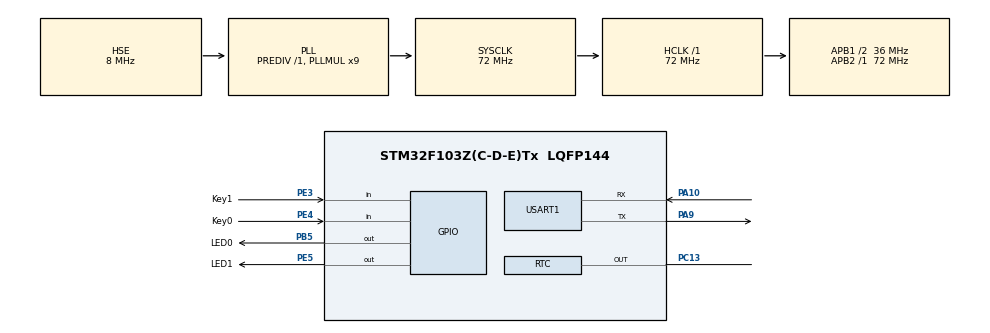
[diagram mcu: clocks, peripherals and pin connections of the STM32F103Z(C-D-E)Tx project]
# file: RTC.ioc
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Mcu.Family=STM32F1
RCC.PLLSourceVirtual=RCC_PLLSOURCE_HSE
PB5.GPIO_ModeDefaultOutputPP=GPIO_MODE_OUTPUT_PP
PC15-OSC32_OUT.Mode=LSE-External-Oscillator
PA10.Mode=Asynchronous
PC13-TAMPER-RTC.Signal=RTC_OUT
VP_RTC_VS_RTC_Activate.Mode=RTC_Enabled
RTC.WeekDay=RTC_WEEKDAY_THURSDAY
RCC.APB1CLKDivider=RCC_HCLK_DIV2
PC14-OSC32_IN.Signal=RCC_OSC32_IN
RCC.SYSCLKSource=RCC_SYSCLKSOURCE_PLLCLK
ProjectManager.StackSize=0x400
PA13.Signal=SYS_JTMS-SWDIO
PA9.Mode=Asynchronous
PE5.GPIO_PuPd=GPIO_PULLUP
ProjectManager.TargetToolchain=MDK-ARM V5
RTC.Year=21
RCC.HCLKFreq_Value=72000000
RCC.APB2TimFreq_Value=72000000
PA9.Signal=USART1_TX
PB5.PinState=GPIO_PIN_SET
RTC.Format=RTC_FORMAT_BCD
PE5.Signal=GPIO_Output
OSC_IN.Signal=RCC_OSC_IN
RCC.USBFreq_Value=72000000
OSC_OUT.Mode=HSE-External-Oscillator
PC15-OSC32_OUT.Signal=RCC_OSC32_OUT
OSC_OUT.Signal=RCC_OSC_OUT
RCC.AHBFreq_Value=72000000
RTC.Minutes=15
board=custom
RCC.RTCClockSelection=RCC_RTCCLKSOURCE_LSE
RCC.PLLMUL=RCC_PLL_MUL9
PC13-TAMPER-RTC.Mode=RTC OUT
RCC.APB2Freq_Value=72000000
RTC.Month=RTC_MONTH_DECEMBER
PC14-OSC32_IN.Mode=LSE-External-Oscillator
PA14.Mode=Serial_Wire
PE4.GPIO_Label=Key0
PE5.PinState=GPIO_PIN_SET
PE3.GPIO_PuPd=GPIO_PULLUP
PA13.Mode=Serial_Wire
PE4.Signal=GPIO_Input
Mcu.Name=STM32F103Z(C-D-E)Tx
PE4.GPIO_PuPd=GPIO_PULLUP
RCC.SYSCLKFreq_VALUE=72000000
RTC.Hours=16
Mcu.Package=LQFP144
PB5.Signal=GPIO_Output
OSC_IN.Mode=HSE-External-Oscillator
PB5.GPIO_PuPd=GPIO_PULLUP
PE5.GPIO_Label=LED1
USART1.VirtualMode=VM_ASYNC
PA10.Signal=USART1_RX
PA14.Signal=SYS_JTCK-SWCLK
VP_RTC_VS_RTC_Calendar.Mode=RTC_Calendar
ProjectManager.HeapSize=0x200
PE5.GPIO_ModeDefaultOutputPP=GPIO_MODE_OUTPUT_PP
PB5.GPIO_Speed=GPIO_SPEED_FREQ_HIGH
NVIC.PriorityGroup=NVIC_PRIORITYGROUP_4
PB5.GPIO_Label=LED0
PE5.GPIO_Speed=GPIO_SPEED_FREQ_HIGH
RCC.APB1TimFreq_Value=72000000
PE3.Signal=GPIO_Input
PE3.GPIO_Label=Key1
RCC.APB1Freq_Value=36000000
RTC.Date=9

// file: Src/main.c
/* USER CODE BEGIN Header */
/**
  ******************************************************************************
  * @file           : main.c
  * @brief          : Main program body
  ******************************************************************************
  * @attention
  *
  * <h2><center>&copy; Copyright (c) 2021 STMicroelectronics.
  * All rights reserved.</center></h2>
  *
  * This software component is licensed by ST under BSD 3-Clause license,
  * the "License"; You may not use this file except in compliance with the
  * License. You may obtain a copy of the License at:
  *                        opensource.org/licenses/BSD-3-Clause
  *
  ******************************************************************************
  */
/* USER CODE END Header */
#include "main.h"
#include "rtc.h"
#include "usart.h"
#include "gpio.h"

/* USER CODE BEGIN Includes */
#include "stdio.h"
/* USER CODE END Includes */

/* USER CODE BEGIN PTD */
RTC_DateTypeDef GetData;  //获得日期结构体

RTC_TimeTypeDef GetTime;   //获得时间结构体

/* USER CODE END PTD */

void SystemClock_Config(void);

int main(void)
{

  /* MCU Configuration--------------------------------------------------------*/

  /* Reset of all peripherals, Initializes the Flash interface and the Systick. */
  HAL_Init();

  /* Configure the system clock */
  SystemClock_Config();

  /* Initialize all configured peripherals */
  MX_GPIO_Init();
  MX_RTC_Init();
  MX_USART1_UART_Init();

  /* Infinite loop */
  /* USER CODE BEGIN WHILE */
	while (1)
	{
		/* Get the RTC current Time */
		HAL_RTC_GetTime(&hrtc, &GetTime, RTC_FORMAT_BIN);
		/* Get the RTC current Date */
		HAL_RTC_GetDate(&hrtc, &GetData, RTC_FORMAT_BIN);

		/* Display date Format : yy/mm/dd */
		printf("%02d/%02d/%02d\r\n",2000 + GetData.Year, GetData.Month, GetData.Date);
		/* Display time Format : hh:mm:ss */
		printf("%02d:%02d:%02d\r\n",GetTime.Hours, GetTime.Minutes, GetTime.Seconds);

		printf("\r\n");

		HAL_Delay(1000);
    /* USER CODE END WHILE */

	}
}

void SystemClock_Config(void)
{
  RCC_OscInitTypeDef RCC_OscInitStruct = {0};
  RCC_ClkInitTypeDef RCC_ClkInitStruct = {0};
  RCC_PeriphCLKInitTypeDef PeriphClkInit = {0};

  /** Initializes the RCC Oscillators according to the specified parameters
  * in the RCC_OscInitTypeDef structure.
  */
  RCC_OscInitStruct.OscillatorType = RCC_OSCILLATORTYPE_HSE|RCC_OSCILLATORTYPE_LSE;
  RCC_OscInitStruct.HSEState = RCC_HSE_ON;
  RCC_OscInitStruct.HSEPredivValue = RCC_HSE_PREDIV_DIV1;
  RCC_OscInitStruct.LSEState = RCC_LSE_ON;
  RCC_OscInitStruct.HSIState = RCC_HSI_ON;
  RCC_OscInitStruct.PLL.PLLState = RCC_PLL_ON;
  RCC_OscInitStruct.PLL.PLLSource = RCC_PLLSOURCE_HSE;
  RCC_OscInitStruct.PLL.PLLMUL = RCC_PLL_MUL9;
  if (HAL_RCC_OscConfig(&RCC_OscInitStruct) != HAL_OK)
  {
    Error_Handler();
  }
  /** Initializes the CPU, AHB and APB buses clocks
  */
  RCC_ClkInitStruct.ClockType = RCC_CLOCKTYPE_HCLK|RCC_CLOCKTYPE_SYSCLK
                              |RCC_CLOCKTYPE_PCLK1|RCC_CLOCKTYPE_PCLK2;
  RCC_ClkInitStruct.SYSCLKSource = RCC_SYSCLKSOURCE_PLLCLK;
  RCC_ClkInitStruct.AHBCLKDivider = RCC_SYSCLK_DIV1;
  RCC_ClkInitStruct.APB1CLKDivider = RCC_HCLK_DIV2;
  RCC_ClkInitStruct.APB2CLKDivider = RCC_HCLK_DIV1;

  if (HAL_RCC_ClockConfig(&RCC_ClkInitStruct, FLASH_LATENCY_2) != HAL_OK)
  {
    Error_Handler();
  }
  PeriphClkInit.PeriphClockSelection = RCC_PERIPHCLK_RTC;
  PeriphClkInit.RTCClockSelection = RCC_RTCCLKSOURCE_LSE;
  if (HAL_RCCEx_PeriphCLKConfig(&PeriphClkInit) != HAL_OK)
  {
    Error_Handler();
  }
}

/* USER CODE BEGIN 4 */

int fputc(int ch,FILE *f)
{
 uint8_t temp[1]={ch};
 HAL_UART_Transmit(&huart1,temp,1,2);
 return ch;
}

/* USER CODE END 4 */

void Error_Handler(void)
{
}

/************************ (C) COPYRIGHT STMicroelectronics *****END OF FILE****/
